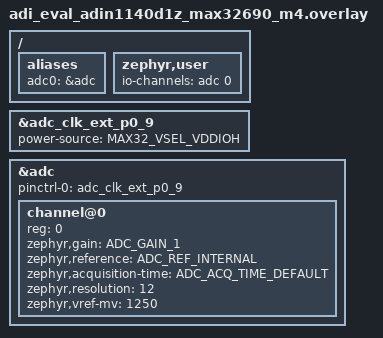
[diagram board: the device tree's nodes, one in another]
/*
 * Copyright (c) 2026 Analog Devices, Inc.
 *
 * SPDX-License-Identifier: Apache-2.0
 */

/ {
	aliases {
		adc0 = &adc;
	};

	zephyr,user {
		io-channels = <&adc 0>;
	};
};

&adc_clk_ext_p0_9 {
	power-source = <MAX32_VSEL_VDDIOH>;
};

&adc {
	status = "okay";
	pinctrl-0 = <&adc_clk_ext_p0_9>;
	pinctrl-names = "default";

	#address-cells = <1>;
	#size-cells = <0>;
	#io-channel-cells = <1>;

	channel@0 {
		reg = <0>;
		zephyr,gain = "ADC_GAIN_1";
		zephyr,reference = "ADC_REF_INTERNAL";
		zephyr,acquisition-time = <ADC_ACQ_TIME_DEFAULT>;
		zephyr,resolution = <12>;
		zephyr,vref-mv = <1250>;
	};
};
